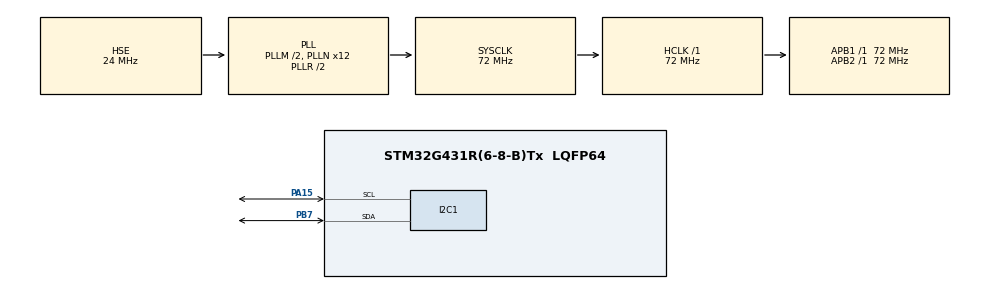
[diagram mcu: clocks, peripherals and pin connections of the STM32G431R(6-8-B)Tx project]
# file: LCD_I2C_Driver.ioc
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I2C1.Timing=0x10808DD3
Mcu.Family=STM32G4
Mcu.Name=STM32G431R(6-8-B)Tx
Mcu.Package=LQFP64
NVIC.PriorityGroup=NVIC_PRIORITYGROUP_4
PA13.Mode=Serial_Wire
PA13.Signal=SYS_JTMS-SWDIO
PA14.Mode=Serial_Wire
PA14.Signal=SYS_JTCK-SWCLK
PA15.Mode=I2C
PA15.Signal=I2C1_SCL
PB7.Mode=I2C
PB7.Signal=I2C1_SDA
PF0-OSC_IN.Mode=HSE-External-Oscillator
PF0-OSC_IN.Signal=RCC_OSC_IN
PF1-OSC_OUT.Mode=HSE-External-Oscillator
PF1-OSC_OUT.Signal=RCC_OSC_OUT
ProjectManager.HeapSize=0x200
ProjectManager.StackSize=0x400
ProjectManager.TargetToolchain=STM32CubeIDE
RCC.ADC12Freq_Value=72000000
RCC.AHBFreq_Value=72000000
RCC.APB1Freq_Value=72000000
RCC.APB1TimFreq_Value=72000000
RCC.APB2Freq_Value=72000000
RCC.APB2TimFreq_Value=72000000
RCC.CortexFreq_Value=72000000
RCC.EXTERNAL_CLOCK_VALUE=12288000
RCC.HCLKFreq_Value=72000000
RCC.HSE_VALUE=24000000
RCC.HSI48_VALUE=48000000
RCC.HSI_VALUE=16000000
RCC.LSE_VALUE=32768
RCC.PLLM=RCC_PLLM_DIV2
RCC.PLLN=12
RCC.PLLSourceVirtual=RCC_PLLSOURCE_HSE
RCC.SYSCLKFreq_VALUE=72000000
RCC.SYSCLKSource=RCC_SYSCLKSOURCE_PLLCLK
RCC.USBFreq_Value=72000000
RCC.VCOOutputFreq_Value=144000000
board=custom

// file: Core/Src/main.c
/* USER CODE BEGIN Header */
/**
  ******************************************************************************
  * @file           : main.c
  * @brief          : Main program body
  ******************************************************************************
  * @attention
  *
  * Copyright (c) 2023 STMicroelectronics.
  * All rights reserved.
  *
  * This software is licensed under terms that can be found in the LICENSE file
  * in the root directory of this software component.
  * If no LICENSE file comes with this software, it is provided AS-IS.
  *
  ******************************************************************************
  */
/* USER CODE END Header */
#include "main.h"

/* USER CODE BEGIN Includes */
#include "i2c-lcd.h"

/* USER CODE END Includes */

I2C_HandleTypeDef hi2c1;

void SystemClock_Config(void);
static void MX_GPIO_Init(void);
static void MX_I2C1_Init(void);

int main(void)
{

  /* MCU Configuration--------------------------------------------------------*/

  /* Reset of all peripherals, Initializes the Flash interface and the Systick. */
  HAL_Init();

  /* Configure the system clock */
  SystemClock_Config();

  /* Initialize all configured peripherals */
  MX_GPIO_Init();
  MX_I2C1_Init();
  /* USER CODE BEGIN 2 */
  lcd_init();
  lcd_send_string("Hello World");
  HAL_Delay(1000);

  /* USER CODE END 2 */

  /* Infinite loop */
  while (1)
  {

  }
}

void SystemClock_Config(void)
{
  RCC_OscInitTypeDef RCC_OscInitStruct = {0};
  RCC_ClkInitTypeDef RCC_ClkInitStruct = {0};

  /** Configure the main internal regulator output voltage
  */
  HAL_PWREx_ControlVoltageScaling(PWR_REGULATOR_VOLTAGE_SCALE1);

  /** Initializes the RCC Oscillators according to the specified parameters
  * in the RCC_OscInitTypeDef structure.
  */
  RCC_OscInitStruct.OscillatorType = RCC_OSCILLATORTYPE_HSE;
  RCC_OscInitStruct.HSEState = RCC_HSE_ON;
  RCC_OscInitStruct.PLL.PLLState = RCC_PLL_ON;
  RCC_OscInitStruct.PLL.PLLSource = RCC_PLLSOURCE_HSE;
  RCC_OscInitStruct.PLL.PLLM = RCC_PLLM_DIV2;
  RCC_OscInitStruct.PLL.PLLN = 12;
  RCC_OscInitStruct.PLL.PLLP = RCC_PLLP_DIV2;
  RCC_OscInitStruct.PLL.PLLQ = RCC_PLLQ_DIV2;
  RCC_OscInitStruct.PLL.PLLR = RCC_PLLR_DIV2;
  if (HAL_RCC_OscConfig(&RCC_OscInitStruct) != HAL_OK)
  {
    Error_Handler();
  }

  /** Initializes the CPU, AHB and APB buses clocks
  */
  RCC_ClkInitStruct.ClockType = RCC_CLOCKTYPE_HCLK|RCC_CLOCKTYPE_SYSCLK
                              |RCC_CLOCKTYPE_PCLK1|RCC_CLOCKTYPE_PCLK2;
  RCC_ClkInitStruct.SYSCLKSource = RCC_SYSCLKSOURCE_PLLCLK;
  RCC_ClkInitStruct.AHBCLKDivider = RCC_SYSCLK_DIV1;
  RCC_ClkInitStruct.APB1CLKDivider = RCC_HCLK_DIV1;
  RCC_ClkInitStruct.APB2CLKDivider = RCC_HCLK_DIV1;

  if (HAL_RCC_ClockConfig(&RCC_ClkInitStruct, FLASH_LATENCY_2) != HAL_OK)
  {
    Error_Handler();
  }
}

static void MX_I2C1_Init(void)
{

  hi2c1.Instance = I2C1;
  hi2c1.Init.Timing = 0x10808DD3;
  hi2c1.Init.OwnAddress1 = 0;
  hi2c1.Init.AddressingMode = I2C_ADDRESSINGMODE_7BIT;
  hi2c1.Init.DualAddressMode = I2C_DUALADDRESS_DISABLE;
  hi2c1.Init.OwnAddress2 = 0;
  hi2c1.Init.OwnAddress2Masks = I2C_OA2_NOMASK;
  hi2c1.Init.GeneralCallMode = I2C_GENERALCALL_DISABLE;
  hi2c1.Init.NoStretchMode = I2C_NOSTRETCH_DISABLE;
  if (HAL_I2C_Init(&hi2c1) != HAL_OK)
  {
    Error_Handler();
  }

  /** Configure Analogue filter
  */
  if (HAL_I2CEx_ConfigAnalogFilter(&hi2c1, I2C_ANALOGFILTER_ENABLE) != HAL_OK)
  {
    Error_Handler();
  }

  /** Configure Digital filter
  */
  if (HAL_I2CEx_ConfigDigitalFilter(&hi2c1, 0) != HAL_OK)
  {
    Error_Handler();
  }

}

static void MX_GPIO_Init(void)
{

  /* GPIO Ports Clock Enable */
  __HAL_RCC_GPIOF_CLK_ENABLE();
  __HAL_RCC_GPIOA_CLK_ENABLE();
  __HAL_RCC_GPIOB_CLK_ENABLE();

}

void Error_Handler(void)
{
  __disable_irq();
  while (1)
  {
  }
}
